# STM32F410TBY7 register map
File version: 1.0
Registers are 32-bit, access not given, reset 0x0 unless marked. A register's access mark holds for its fields unless they carry their own. Offsets are from the block's base; [hi:lo] are bit positions; {n}, {i} and the like mark numbered series.

## WWDG
Base 0x40002C00
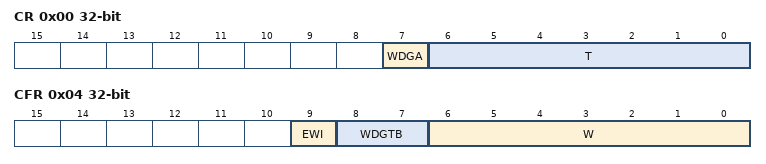
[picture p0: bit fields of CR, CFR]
0x00 CR
  [7] WDGA, [6:0] T
0x04 CFR
  [9] EWI, [8:7] WDGTB, [6:0] W
0x08 SR
  [0] EWIF

## IWDG
Base 0x40003000
0x00 KR
  [15:0] KEY
0x04 PR
  [2:0] PR
0x08 RLR
  [11:0] RL
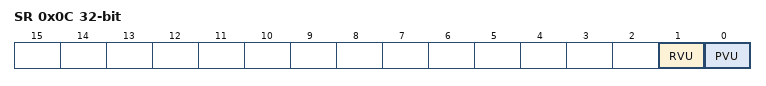
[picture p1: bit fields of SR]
0x0C SR
  [1] RVU, [0] PVU

## USART2
Base 0x40004400
Same registers: USART1 0x40011000
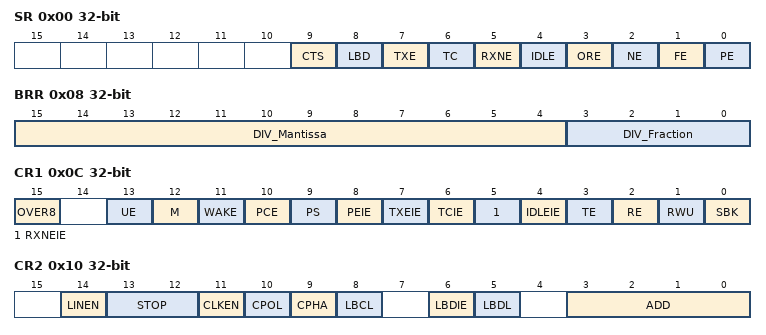
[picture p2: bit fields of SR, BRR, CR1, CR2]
0x00 SR
  [9] CTS, [8] LBD, [7] TXE, [6] TC, [5] RXNE, [4] IDLE, [3] ORE, [2] NE, [1] FE, [0] PE
0x04 DR
  [8:0] DR
0x08 BRR
  [15:4] DIV_Mantissa, [3:0] DIV_Fraction
0x0C CR1
  [15] OVER8, [13] UE, [12] M, [11] WAKE, [10] PCE, [9] PS, [8] PEIE, [7] TXEIE, [6] TCIE, [5] RXNEIE, [4] IDLEIE, [3] TE, [2] RE, [1] RWU, [0] SBK
0x10 CR2
  [14] LINEN, [13:12] STOP, [11] CLKEN, [10] CPOL, [9] CPHA, [8] LBCL, [6] LBDIE, [5] LBDL, [3:0] ADD
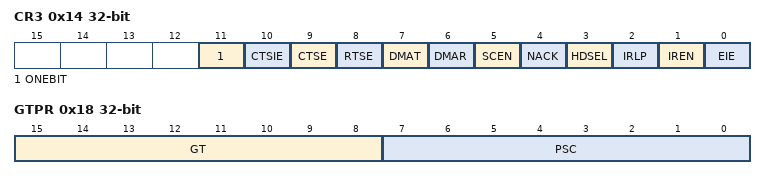
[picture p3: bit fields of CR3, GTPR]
0x14 CR3
  [11] ONEBIT, [10] CTSIE, [9] CTSE, [8] RTSE, [7] DMAT, [6] DMAR, [5] SCEN, [4] NACK, [3] HDSEL, [2] IRLP, [1] IREN, [0] EIE
0x18 GTPR
  [15:8] GT, [7:0] PSC

## I2C1
Base 0x40005400
Same registers: I2C2 0x40005800
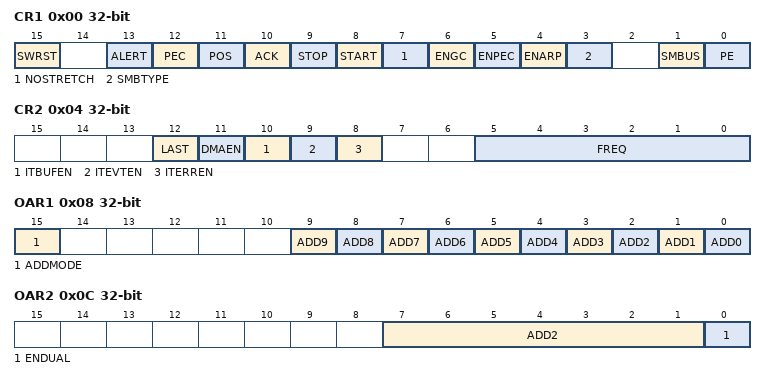
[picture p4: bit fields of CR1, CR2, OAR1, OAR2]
0x00 CR1
  [15] SWRST, [13] ALERT, [12] PEC, [11] POS, [10] ACK, [9] STOP, [8] START, [7] NOSTRETCH, [6] ENGC, [5] ENPEC, [4] ENARP, [3] SMBTYPE, [1] SMBUS, [0] PE
0x04 CR2
  [12] LAST, [11] DMAEN, [10] ITBUFEN, [9] ITEVTEN, [8] ITERREN, [5:0] FREQ
0x08 OAR1
  [15] ADDMODE, [n] ADD{n} (n=0..9)
0x0C OAR2
  [7:1] ADD2, [0] ENDUAL
0x10 DR
  [7:0] DR
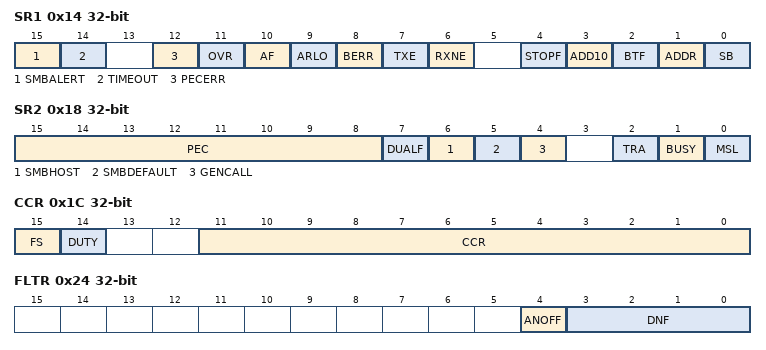
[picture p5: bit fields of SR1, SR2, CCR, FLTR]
0x14 SR1
  [15] SMBALERT, [14] TIMEOUT, [12] PECERR, [11] OVR, [10] AF, [9] ARLO, [8] BERR, [7] TXE, [6] RXNE, [4] STOPF, [3] ADD10, [2] BTF, [1] ADDR, [0] SB
0x18 SR2
  [15:8] PEC, [7] DUALF, [6] SMBHOST, [5] SMBDEFAULT, [4] GENCALL, [2] TRA, [1] BUSY, [0] MSL
0x1C CCR
  [15] FS, [14] DUTY, [11:0] CCR
0x20 TRISE
  [5:0] TRISE
0x24 FLTR
  [4] ANOFF, [3:0] DNF

## FMPI2C1
Base 0x40006000
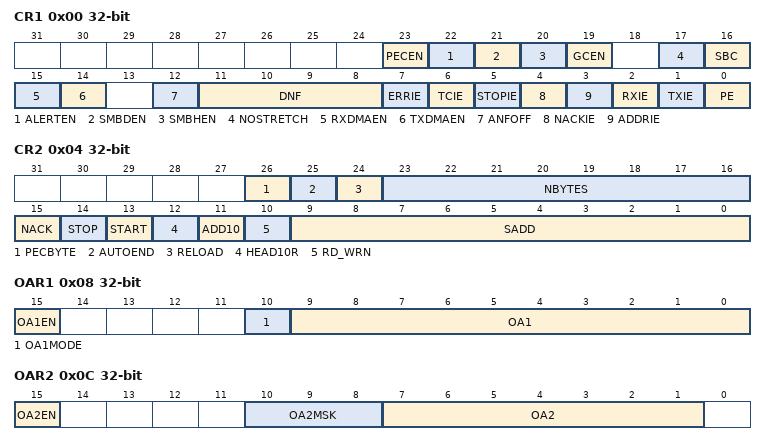
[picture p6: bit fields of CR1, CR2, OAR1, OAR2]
0x00 CR1
  [23] PECEN, [22] ALERTEN, [21] SMBDEN, [20] SMBHEN, [19] GCEN, [17] NOSTRETCH, [16] SBC, [15] RXDMAEN, [14] TXDMAEN, [12] ANFOFF, [11:8] DNF, [7] ERRIE, [6] TCIE, [5] STOPIE, [4] NACKIE, [3] ADDRIE, [2] RXIE, [1] TXIE, [0] PE
0x04 CR2
  [26] PECBYTE, [25] AUTOEND, [24] RELOAD, [23:16] NBYTES, [15] NACK, [14] STOP, [13] START, [12] HEAD10R, [11] ADD10, [10] RD_WRN, [9:0] SADD
0x08 OAR1
  [15] OA1EN, [10] OA1MODE, [9:0] OA1
0x0C OAR2
  [15] OA2EN, [10:8] OA2MSK, [7:1] OA2
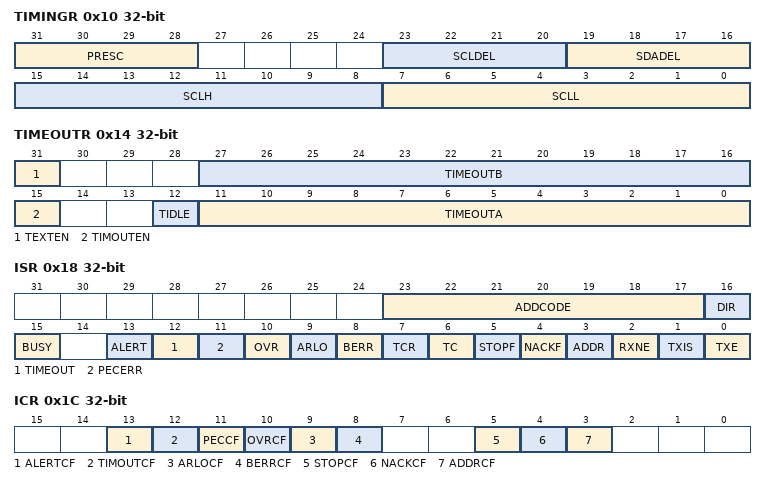
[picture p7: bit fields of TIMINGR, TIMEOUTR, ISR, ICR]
0x10 TIMINGR
  [31:28] PRESC, [23:20] SCLDEL, [19:16] SDADEL, [15:8] SCLH, [7:0] SCLL
0x14 TIMEOUTR
  [31] TEXTEN, [27:16] TIMEOUTB, [15] TIMOUTEN, [12] TIDLE, [11:0] TIMEOUTA
0x18 ISR
  [23:17] ADDCODE, [16] DIR, [15] BUSY, [13] ALERT, [12] TIMEOUT, [11] PECERR, [10] OVR, [9] ARLO, [8] BERR, [7] TCR, [6] TC, [5] STOPF, [4] NACKF, [3] ADDR, [2] RXNE, [1] TXIS, [0] TXE
0x1C ICR
  [13] ALERTCF, [12] TIMOUTCF, [11] PECCF, [10] OVRCF, [9] ARLOCF, [8] BERRCF, [5] STOPCF, [4] NACKCF, [3] ADDRCF
0x20 PECR
  [7:0] PEC
0x24 RXDR
  [7:0] RXDATA
0x28 TXDR
  [7:0] TXDATA

## PWR
Base 0x40007000
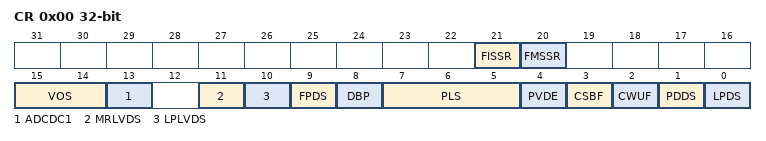
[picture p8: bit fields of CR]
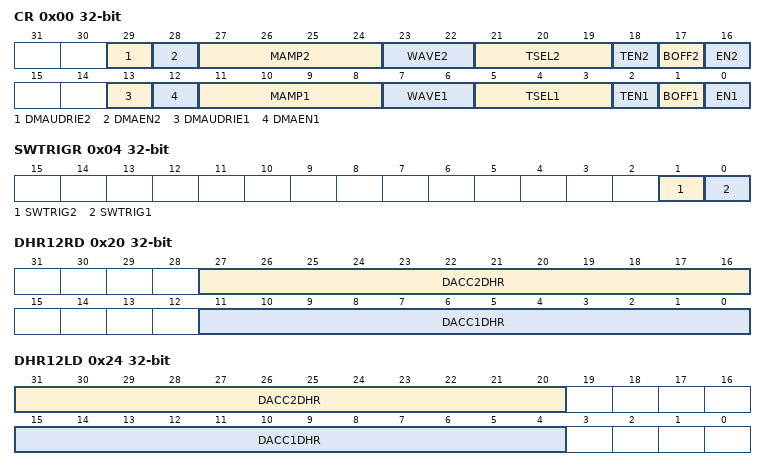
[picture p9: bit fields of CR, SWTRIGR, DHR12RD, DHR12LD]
0x00 CR
  [21] FISSR, [20] FMSSR, [15:14] VOS, [13] ADCDC1, [11] MRLVDS, [10] LPLVDS, [9] FPDS, [8] DBP, [7:5] PLS, [4] PVDE, [3] CSBF, [2] CWUF, [1] PDDS, [0] LPDS
0x04 CSR
  [14] VOSRDY, [9] BRE, [8] EWUP1, [7] EWUP2, [8:6] EWUP3, [3] BRR, [2] PVDO, [1] SBF, [0] WUF

## DAC1
Base 0x40007400
0x00 CR
  [29] DMAUDRIE2, [28] DMAEN2, [27:24] MAMP2, [23:22] WAVE2, [21:19] TSEL2, [18] TEN2, [17] BOFF2, [16] EN2, [13] DMAUDRIE1, [12] DMAEN1, [11:8] MAMP1, [7:6] WAVE1, [5:3] TSEL1, [2] TEN1, [1] BOFF1, [0] EN1
0x04 SWTRIGR
  [1] SWTRIG2, [0] SWTRIG1
0x08 DHR12R1
  [11:0] DACC1DHR
0x0C DHR12L1
  [15:4] DACC1DHR
0x10 DHR8R1
  [7:0] DACC1DHR
0x14 DHR12R2
  [11:0] DACC2DHR
0x18 DHR12L2
  [15:4] DACC2DHR
0x1C DHR8R2
  [7:0] DACC2DHR
0x20 DHR12RD
  [27:16] DACC2DHR, [11:0] DACC1DHR
0x24 DHR12LD
  [31:20] DACC2DHR, [15:4] DACC1DHR
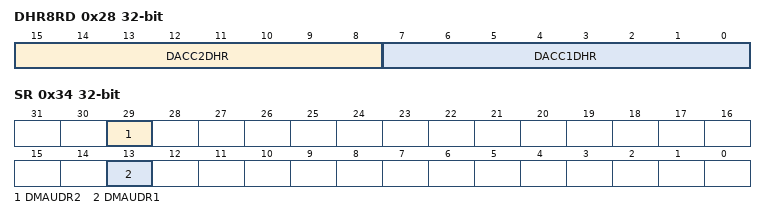
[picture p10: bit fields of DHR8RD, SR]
0x28 DHR8RD
  [15:8] DACC2DHR, [7:0] DACC1DHR
0x2C DOR1
  [11:0] DACC1DOR
0x30 DOR2
  [11:0] DACC2DOR
0x34 SR
  [29] DMAUDR2, [13] DMAUDR1
